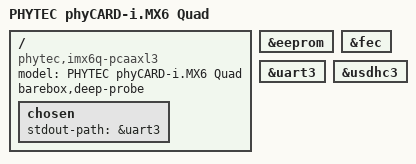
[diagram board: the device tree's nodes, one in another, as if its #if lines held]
// SPDX-License-Identifier: (GPL-2.0-or-later)
/*
 * Copyright (C) 2014 PHYTEC Messtechnik GmbH
 * Author: Christian Hemp <c.hemp@phytec.de>
 */

/dts-v1/;

#ifdef CONFIG_BOOTM_FITIMAGE_PUBKEY
#include CONFIG_BOOTM_FITIMAGE_PUBKEY
#endif

#include <arm/nxp/imx/imx6q.dtsi>
#include "imx6q.dtsi"
#include "imx6qdl-phytec-phycard-som.dtsi"

/ {
	model = "PHYTEC phyCARD-i.MX6 Quad";
	compatible = "phytec,imx6q-pcaaxl3", "fsl,imx6q";
	barebox,deep-probe;

	chosen {
		stdout-path = &uart3;
	};
};

&eeprom {
	status = "okay";
};

&fec {
	status = "okay";
};

&uart3 {
	status = "okay";
};

&usdhc3 {
	status = "okay";
};
